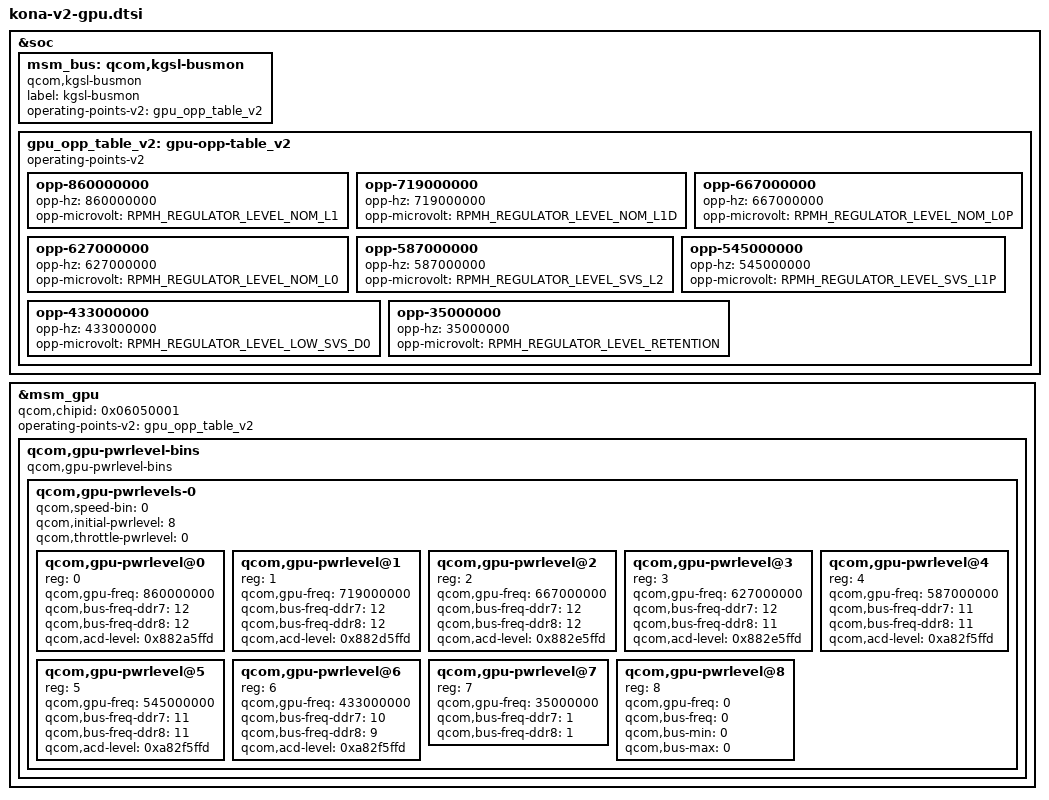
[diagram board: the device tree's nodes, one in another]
&soc {
	msm_bus: qcom,kgsl-busmon {
		label = "kgsl-busmon";
		compatible = "qcom,kgsl-busmon";
		operating-points-v2 = <&gpu_opp_table_v2>;
	};

	gpu_opp_table_v2: gpu-opp-table_v2 {
		compatible = "operating-points-v2";
		
		opp-860000000 {
			opp-hz = /bits/ 64 <860000000>;
			opp-microvolt = <RPMH_REGULATOR_LEVEL_NOM_L1>;
		};
		
		opp-719000000 {
			opp-hz = /bits/ 64 <719000000>;
			opp-microvolt = <RPMH_REGULATOR_LEVEL_NOM_L1D>;
		};

		opp-667000000 {
			opp-hz = /bits/ 64 <667000000>;
			opp-microvolt = <RPMH_REGULATOR_LEVEL_NOM_L0P>;
		};

		opp-627000000 {
			opp-hz = /bits/ 64 <627000000>;
			opp-microvolt = <RPMH_REGULATOR_LEVEL_NOM_L0>;
		};

		opp-587000000 {
			opp-hz = /bits/ 64 <587000000>;
			opp-microvolt = <RPMH_REGULATOR_LEVEL_SVS_L2>;
		};

		opp-545000000 {
			opp-hz = /bits/ 64 <545000000>;
			opp-microvolt = <RPMH_REGULATOR_LEVEL_SVS_L1P>;
		};

		opp-433000000 {
			opp-hz = /bits/ 64 <433000000>;
			opp-microvolt = <RPMH_REGULATOR_LEVEL_LOW_SVS_D0>;
		};

		opp-35000000 {
			opp-hz = /bits/ 64 <35000000>;
			opp-microvolt = <RPMH_REGULATOR_LEVEL_RETENTION>;
		};

	};
};

&msm_gpu {
	qcom,chipid = <0x06050001>;

	/* GPU OPP data */
	operating-points-v2 = <&gpu_opp_table_v2>;

	/delete-property/qcom,initial-pwrlevel;
	/delete-node/qcom,gpu-pwrlevels;

	/* Power levels bins */
	qcom,gpu-pwrlevel-bins {
		compatible="qcom,gpu-pwrlevel-bins";
		#address-cells = <1>;
		#size-cells = <0>;

		qcom,gpu-pwrlevels-0 {
			#address-cells = <1>;
			#size-cells = <0>;
			qcom,speed-bin = <0>;
			qcom,initial-pwrlevel = <8>;
			qcom,throttle-pwrlevel = <0>;

			qcom,gpu-pwrlevel@0 {
				reg = <0>;
				qcom,gpu-freq = <860000000>;

				qcom,bus-freq-ddr7 = <12>;
				qcom,bus-freq-ddr8 = <12>;

				qcom,acd-level = <0x882a5ffd>;
			};

			qcom,gpu-pwrlevel@1 {
				reg = <1>;
				qcom,gpu-freq = <719000000>;

				qcom,bus-freq-ddr7 = <12>;
				qcom,bus-freq-ddr8 = <12>;

				qcom,acd-level = <0x882d5ffd>;
			};

			qcom,gpu-pwrlevel@2 {
				reg = <2>;
				qcom,gpu-freq = <667000000>;

				qcom,bus-freq-ddr7 = <12>;
				qcom,bus-freq-ddr8 = <12>;

				qcom,acd-level = <0x882e5ffd>;
			};

			qcom,gpu-pwrlevel@3 {
				reg = <3>;
				qcom,gpu-freq = <627000000>;

				qcom,bus-freq-ddr7 = <12>;
				qcom,bus-freq-ddr8 = <11>;

				qcom,acd-level = <0x882e5ffd>;
			};

			qcom,gpu-pwrlevel@4 {
				reg = <4>;
				qcom,gpu-freq = <587000000>;

				qcom,bus-freq-ddr7 = <11>;
				qcom,bus-freq-ddr8 = <11>;

				qcom,acd-level = <0xa82f5ffd>;
			};

			qcom,gpu-pwrlevel@5 {
				reg = <5>;
				qcom,gpu-freq = <545000000>;

				qcom,bus-freq-ddr7 = <11>;
				qcom,bus-freq-ddr8 = <11>;

				qcom,acd-level = <0xa82f5ffd>;
			};

			qcom,gpu-pwrlevel@6 {
				reg = <6>;
				qcom,gpu-freq = <433000000>;

				qcom,bus-freq-ddr7 = <10>;
				qcom,bus-freq-ddr8 = <9>;

				qcom,acd-level = <0xa82f5ffd>;
			};

			qcom,gpu-pwrlevel@7 {
				reg = <7>;
				qcom,gpu-freq = <35000000>;

				qcom,bus-freq-ddr7 = <1>;
				qcom,bus-freq-ddr8 = <1>;
			};

			qcom,gpu-pwrlevel@8 {
				reg = <8>;
				qcom,gpu-freq = <0>;
				qcom,bus-freq = <0>;
				qcom,bus-min = <0>;
				qcom,bus-max = <0>;
			};
		};
	};
};
